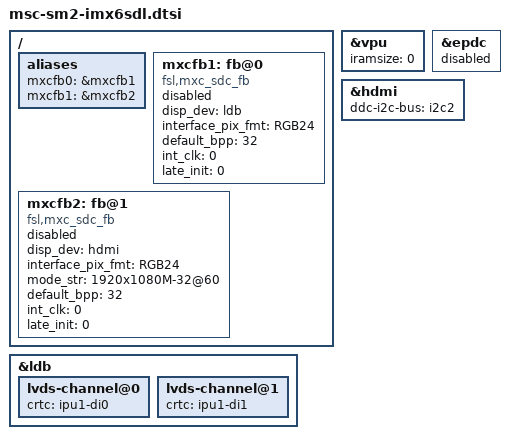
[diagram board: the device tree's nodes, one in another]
/*
 * Copyright 2017 MSC Technologies GmbH 
 *
 * The code contained herein is licensed under the GNU General Public
 * License. You may obtain a copy of the GNU General Public License
 * Version 2 or later at the following locations:
 *
 * http://www.opensource.org/licenses/gpl-license.html
 * http://www.gnu.org/copyleft/gpl.html
 */
#include "skeleton.dtsi"
#include <dt-bindings/gpio/gpio.h>
#include "msc-sm2-imx6x.dtsi"

/ {
	aliases {
		mxcfb0 = &mxcfb1;
		mxcfb1 = &mxcfb2;
	};

	mxcfb1: fb@0 {
		compatible = "fsl,mxc_sdc_fb";
		disp_dev = "ldb";
		interface_pix_fmt = "RGB24";
		default_bpp = <32>;
		int_clk = <0>;
		late_init = <0>;
		status = "disabled";
	};

	mxcfb2: fb@1 {
		compatible = "fsl,mxc_sdc_fb";
		disp_dev = "hdmi";
		interface_pix_fmt = "RGB24";
		mode_str ="1920x1080M-32@60";
		default_bpp = <32>;
		int_clk = <0>;
		late_init = <0>;
		status = "disabled";
	};
};
&vpu {
	iramsize = <0>;
	status = "okay";
};
&epdc {
	status = "disabled";
};

&ldb {
	lvds-channel@0 {
		crtc = "ipu1-di0";
	};

	lvds-channel@1 {
		crtc = "ipu1-di1";
	};
};

&hdmi {
	ddc-i2c-bus = <&i2c2>;
	status = "okay";
};
